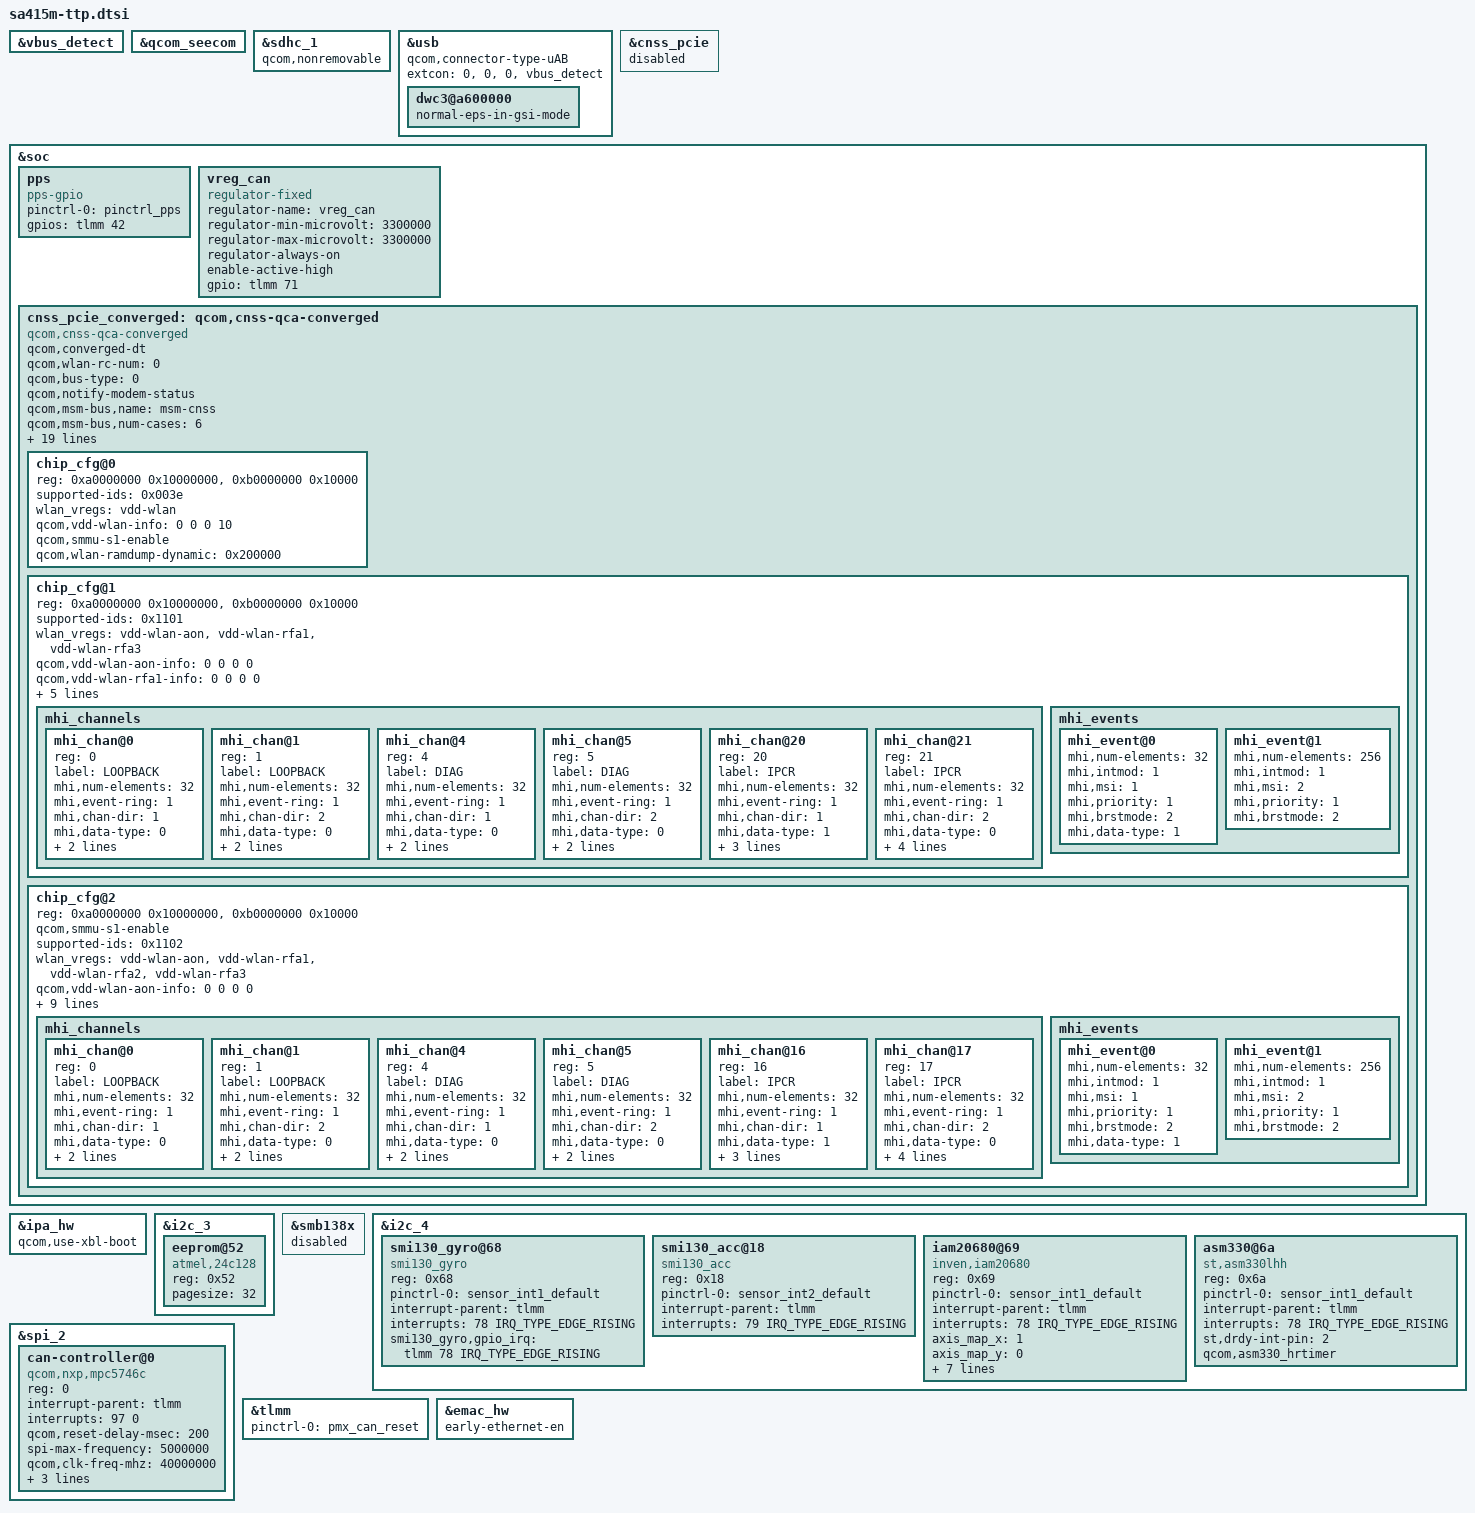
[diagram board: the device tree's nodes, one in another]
/* Copyright (c) 2018-2020, The Linux Foundation. All rights reserved.
 *
 * This program is free software; you can redistribute it and/or modify
 * it under the terms of the GNU General Public License version 2 and
 * only version 2 as published by the Free Software Foundation.
 *
 * This program is distributed in the hope that it will be useful,
 * but WITHOUT ANY WARRANTY; without even the implied warranty of
 * MERCHANTABILITY or FITNESS FOR A PARTICULAR PURPOSE.  See the
 * GNU General Public License for more details.
 */

#include <dt-bindings/msm/msm-bus-ids.h>
#include "sdxpoorwills-mtp.dtsi"

&vbus_detect {
	status = "okay";
};

&qcom_seecom {
	status = "okay";
};

&sdhc_1 {
	qcom,nonremovable;
};

&usb {
	status = "okay";
	qcom,connector-type-uAB;
	extcon = <0>, <0>, <0>, <&vbus_detect>;
	dwc3@a600000 {
		normal-eps-in-gsi-mode;
	};
};

&cnss_pcie {
	status = "disabled";
};

&soc {
	pps {
		compatible = "pps-gpio";
		pinctrl-names = "default";
		pinctrl-0 = <&pinctrl_pps>;
		gpios = <&tlmm 42 GPIO_ACTIVE_HIGH>;
		status = "okay";
	};

	vreg_can: vreg_can {
		compatible = "regulator-fixed";
		regulator-name = "vreg_can";
		regulator-min-microvolt = <3300000>;
		regulator-max-microvolt = <3300000>;
		regulator-always-on;
		enable-active-high;
		gpio = <&tlmm 71 GPIO_ACTIVE_HIGH>;
	};

	cnss_pcie_converged: qcom,cnss-qca-converged {
		compatible = "qcom,cnss-qca-converged";
		qcom,converged-dt;
		qcom,wlan-rc-num = <0>;
		qcom,bus-type=<0>;
		qcom,notify-modem-status;
		qcom,msm-bus,name = "msm-cnss";
		qcom,msm-bus,num-cases = <6>;
		qcom,msm-bus,num-paths = <1>;
		qcom,msm-bus,vectors-KBps =
		/* no vote */
		<MSM_BUS_MASTER_PCIE MSM_BUS_SLAVE_FIRST 0 0>,
		/* idle: 0-18 Mbps, ddr freq: 100 MHz */
		<MSM_BUS_MASTER_PCIE MSM_BUS_SLAVE_FIRST 2250 400000>,
		/* low: 18-60 Mbps, ddr freq: 200 MHz*/
		<MSM_BUS_MASTER_PCIE MSM_BUS_SLAVE_FIRST 7500 800000>,
		/* medium: 60-240 Mbps, ddr freq: 451.2 MHz */
		<MSM_BUS_MASTER_PCIE MSM_BUS_SLAVE_FIRST 30000 1804800>,
		/* high: 240 - 800 Mbps, ddr freq: 451.2 MHz */
		<MSM_BUS_MASTER_PCIE MSM_BUS_SLAVE_FIRST 100000 1804800>,
		/* very high: 800 - 1400 Mbps, ddr freq: 1555.2 MHz */
		<MSM_BUS_MASTER_PCIE MSM_BUS_SLAVE_FIRST 175000 6220800>;

		#address-cells=<1>;
		#size-cells=<1>;
		ranges = <0xa0000000 0xa0000000 0x10000000>,
			  <0xb0000000 0xb0000000 0x10000>;

		vdd-wlan-ctrl1-supply = <&pmxpoorwills_l6>;
		vdd-wlan-ctrl2-supply = <&pmxpoorwills_l6>;
		vdd-wlan-aon-supply = <&pmxpoorwills_l6>;
		vdd-wlan-rfa1-supply = <&pmxpoorwills_l6>;
		vdd-wlan-rfa3-supply = <&pmxpoorwills_l6>;

		wlan_vregs = "vdd-wlan-ctrl1", "vdd-wlan-ctrl2";
		qcom,vdd-wlan-ctrl1-info = <0 0 0 0>;
		qcom,vdd-wlan-ctrl2-info = <0 0 0 0>;
		wlan-en-gpio = <&tlmm 52 0>;
		pinctrl-names = "wlan_en_active", "wlan_en_sleep";
		pinctrl-0 = <&cnss_wlan_en_active>;
		pinctrl-1 = <&cnss_wlan_en_sleep>;

		chip_cfg@0 {
			reg = <0xa0000000 0x10000000>,
				<0xb0000000 0x10000>;
			reg-names = "smmu_iova_base", "smmu_iova_ipa";
			supported-ids = <0x003e>;
			wlan_vregs = "vdd-wlan";
			qcom,vdd-wlan-info = <0 0 0 10>;

			qcom,smmu-s1-enable;
			qcom,wlan-ramdump-dynamic = <0x200000>;
		};

		chip_cfg@1 {
			reg = <0xa0000000 0x10000000>,
				<0xb0000000 0x10000>;
			reg-names = "smmu_iova_base", "smmu_iova_ipa";

			supported-ids = <0x1101>;
			wlan_vregs = "vdd-wlan-aon", "vdd-wlan-rfa1",
				"vdd-wlan-rfa3";
			qcom,vdd-wlan-aon-info = <0 0 0 0>;
			qcom,vdd-wlan-rfa1-info = <0 0 0 0>;
			qcom,vdd-wlan-rfa3-info = <0 0 0 0>;

			qcom,wlan-ramdump-dynamic = <0x400000>;
			mhi,max-channels = <30>;
			mhi,timeout = <10000>;
			qcom,smmu-s1-enable;
			mhi_channels {
				#address-cells = <1>;
				#size-cells = <0>;
				mhi_chan@0 {
					reg = <0>;
					label = "LOOPBACK";
					mhi,num-elements = <32>;
					mhi,event-ring = <1>;
					mhi,chan-dir = <1>;
					mhi,data-type = <0>;
					mhi,doorbell-mode = <2>;
					mhi,ee = <0x14>;
				};

				mhi_chan@1 {
					reg = <1>;
					label = "LOOPBACK";
					mhi,num-elements = <32>;
					mhi,event-ring = <1>;
					mhi,chan-dir = <2>;
					mhi,data-type = <0>;
					mhi,doorbell-mode = <2>;
					mhi,ee = <0x14>;
				};

				mhi_chan@4 {
					reg = <4>;
					label = "DIAG";
					mhi,num-elements = <32>;
					mhi,event-ring = <1>;
					mhi,chan-dir = <1>;
					mhi,data-type = <0>;
					mhi,doorbell-mode = <2>;
					mhi,ee = <0x14>;
				};

				mhi_chan@5 {
					reg = <5>;
					label = "DIAG";
					mhi,num-elements = <32>;
					mhi,event-ring = <1>;
					mhi,chan-dir = <2>;
					mhi,data-type = <0>;
					mhi,doorbell-mode = <2>;
					mhi,ee = <0x14>;
				};

				mhi_chan@20 {
					reg = <20>;
					label = "IPCR";
					mhi,num-elements = <32>;
					mhi,event-ring = <1>;
					mhi,chan-dir = <1>;
					mhi,data-type = <1>;
					mhi,doorbell-mode = <2>;
					mhi,ee = <0x14>;
					mhi,auto-start;
				};

				mhi_chan@21 {
					reg = <21>;
					label = "IPCR";
					mhi,num-elements = <32>;
					mhi,event-ring = <1>;
					mhi,chan-dir = <2>;
					mhi,data-type = <0>;
					mhi,doorbell-mode = <2>;
					mhi,ee = <0x14>;
					mhi,auto-queue;
					mhi,auto-start;
				};
			};

			mhi_events {
				mhi_event@0 {
					mhi,num-elements = <32>;
					mhi,intmod = <1>;
					mhi,msi = <1>;
					mhi,priority = <1>;
					mhi,brstmode = <2>;
					mhi,data-type = <1>;
				};

				mhi_event@1 {
					mhi,num-elements = <256>;
					mhi,intmod = <1>;
					mhi,msi = <2>;
					mhi,priority = <1>;
					mhi,brstmode = <2>;
				};
			};
		};

		chip_cfg@2 {
			reg = <0xa0000000 0x10000000>,
				<0xb0000000 0x10000>;
			reg-names = "smmu_iova_base", "smmu_iova_ipa";
			qcom,smmu-s1-enable;
			supported-ids = <0x1102>;
			wlan_vregs = "vdd-wlan-aon", "vdd-wlan-rfa1",
				"vdd-wlan-rfa2", "vdd-wlan-rfa3";
			qcom,vdd-wlan-aon-info = <0 0 0 0>;
			qcom,vdd-wlan-rfa1-info = <0 0 0 0>;
			qcom,vdd-wlan-rfa2-info = <0 0 0 0>;
			qcom,vdd-wlan-rfa3-info = <0 0 0 0>;

			qcom,wlan-ramdump-dynamic = <0x300000>;
			mhi,max-channels = <30>;
			mhi,timeout = <10000>;
			mhi,ee = <0x3>, <0x4>;
			mhi,ee-names = "SBL", "RDDM";
			mhi,bhie-offset = <0x0324>;

			mhi_channels {
				mhi_chan@0 {
					reg = <0>;
					label = "LOOPBACK";
					mhi,num-elements = <32>;
					mhi,event-ring = <1>;
					mhi,chan-dir = <1>;
					mhi,data-type = <0>;
					mhi,doorbell-mode = <2>;
					mhi,ee = <0x14>;
				};

				mhi_chan@1 {
					reg = <1>;
					label = "LOOPBACK";
					mhi,num-elements = <32>;
					mhi,event-ring = <1>;
					mhi,chan-dir = <2>;
					mhi,data-type = <0>;
					mhi,doorbell-mode = <2>;
					mhi,ee = <0x14>;
				};

				mhi_chan@4 {
					reg = <4>;
					label = "DIAG";
					mhi,num-elements = <32>;
					mhi,event-ring = <1>;
					mhi,chan-dir = <1>;
					mhi,data-type = <0>;
					mhi,doorbell-mode = <2>;
					mhi,ee = <0x14>;
				};

				mhi_chan@5 {
					reg = <5>;
					label = "DIAG";
					mhi,num-elements = <32>;
					mhi,event-ring = <1>;
					mhi,chan-dir = <2>;
					mhi,data-type = <0>;
					mhi,doorbell-mode = <2>;
					mhi,ee = <0x14>;
				};

				mhi_chan@16 {
					reg = <16>;
					label = "IPCR";
					mhi,num-elements = <32>;
					mhi,event-ring = <1>;
					mhi,chan-dir = <1>;
					mhi,data-type = <1>;
					mhi,doorbell-mode = <2>;
					mhi,ee = <0x14>;
					mhi,auto-start;
				};

				mhi_chan@17 {
					reg = <17>;
					label = "IPCR";
					mhi,num-elements = <32>;
					mhi,event-ring = <1>;
					mhi,chan-dir = <2>;
					mhi,data-type = <0>;
					mhi,doorbell-mode = <2>;
					mhi,ee = <0x14>;
					mhi,auto-queue;
					mhi,auto-start;
				};
			};

			mhi_events {
				mhi_event@0 {
					mhi,num-elements = <32>;
					mhi,intmod = <1>;
					mhi,msi = <1>;
					mhi,priority = <1>;
					mhi,brstmode = <2>;
					mhi,data-type = <1>;
				};

				mhi_event@1 {
					mhi,num-elements = <256>;
					mhi,intmod = <1>;
					mhi,msi = <2>;
					mhi,priority = <1>;
					mhi,brstmode = <2>;
				};
			};
		};
	};
};

&ipa_hw {
	qcom,use-xbl-boot;
};

&i2c_3 {
	eeprom@52 {
		compatible = "atmel,24c128";
		reg = <0x52>;
		pagesize = <32>;
	};
};

&smb138x {
	status = "disabled";
};

&i2c_4 {
	status = "okay";

	smi130_gyro@68 {
		compatible = "smi130_gyro";
		reg = <0x68>;
		pinctrl-names = "default";
		pinctrl-0 = <&sensor_int1_default>;
		interrupt-parent = <&tlmm>;
		interrupts = <78 IRQ_TYPE_EDGE_RISING>;
		smi130_gyro,gpio_irq = <&tlmm 78 IRQ_TYPE_EDGE_RISING>;
	};

	smi130_acc@18 {
		compatible = "smi130_acc";
		reg = <0x18>;
		pinctrl-names = "default";
		pinctrl-0 = <&sensor_int2_default>;
		interrupt-parent = <&tlmm>;
		interrupts = <79 IRQ_TYPE_EDGE_RISING>;
	};

	iam20680@69 {
	       compatible = "inven,iam20680";
	       reg = <0x69>;
	       pinctrl-names = "default";
	       pinctrl-0 = <&sensor_int1_default>;
	       interrupt-parent = <&tlmm>;
	       interrupts = <78 IRQ_TYPE_EDGE_RISING>;
	       axis_map_x = <1>;
	       axis_map_y = <0>;
	       axis_map_z = <2>;
	       negate_x = <1>;
	       negate_y = <0>;
	       negate_z = <0>;
	       inven,secondary_type = "none";
	       inven,aux_type = "none";
	       inven,read_only_slave_type = "none";
	};

	asm330@6a {
	       compatible = "st,asm330lhh";
	       reg = <0x6a>;
	       pinctrl-names = "default";
	       pinctrl-0 = <&sensor_int1_default>;
	       interrupt-parent = <&tlmm>;
	       interrupts = <78 IRQ_TYPE_EDGE_RISING>;
	       st,drdy-int-pin= <2>;
	       qcom,asm330_hrtimer;
	};
};

&spi_2 {
	status = "okay";

	can-controller@0 {
		compatible = "qcom,nxp,mpc5746c";
		reg = <0>;
		interrupt-parent = <&tlmm>;
		interrupts = <97 0>;
		qcom,reset-delay-msec = <200>;
		spi-max-frequency = <5000000>;
		qcom,clk-freq-mhz = <40000000>;
		qcom,max-can-channels = <1>;
		qcom,bits-per-word = <8>;
		qcom,support-can-fd;
	};
};

&tlmm {
	/* Set these up as hogs */
	pinctrl-names = "default";
	pinctrl-0 = <&pmx_can_reset>;
};

&emac_hw {
	early-ethernet-en;
};
